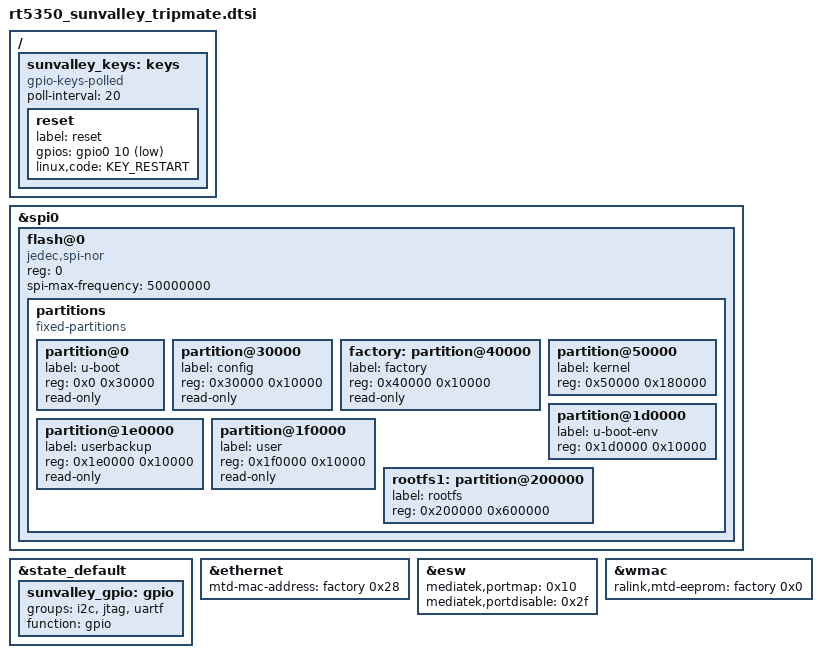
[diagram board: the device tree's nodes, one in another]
#include "rt5350.dtsi"

#include <dt-bindings/gpio/gpio.h>
#include <dt-bindings/input/input.h>

/ {
	sunvalley_keys: keys {
		compatible = "gpio-keys-polled";
		poll-interval = <20>;

		reset {
			label = "reset";
			gpios = <&gpio0 10 GPIO_ACTIVE_LOW>;
			linux,code = <KEY_RESTART>;
		};
	};
};

&spi0 {
	status = "okay";

	flash@0 {
		compatible = "jedec,spi-nor";
		reg = <0>;
		spi-max-frequency = <50000000>;

		partitions {
			compatible = "fixed-partitions";
			#address-cells = <1>;
			#size-cells = <1>;

			partition@0 {
				label = "u-boot";
				reg = <0x0 0x30000>;
				read-only;
			};

			partition@30000 {
				label = "config";
				reg = <0x30000 0x10000>;
				read-only;
			};

			factory: partition@40000 {
				label = "factory";
				reg = <0x40000 0x10000>;
				read-only;
			};

			partition@50000 {
				label = "kernel";
				reg = <0x50000 0x180000>;
			};

			partition@1d0000 {
				label = "u-boot-env";
				reg = <0x1d0000 0x10000>;
			};

			partition@1e0000 {
				label = "userbackup";
				reg = <0x1e0000 0x10000>;
				read-only;
			};

			partition@1f0000 {
				label = "user";
				reg = <0x1f0000 0x10000>;
				read-only;
			};

			rootfs1: partition@200000 {
				label = "rootfs";
				reg = <0x200000 0x600000>;
			};
		};
	};
};

&state_default {
	sunvalley_gpio: gpio {
		groups = "i2c", "jtag", "uartf";
		function = "gpio";
	};
};

&ethernet {
	mtd-mac-address = <&factory 0x28>;
};

&esw {
	mediatek,portmap = <0x10>;
	mediatek,portdisable = <0x2f>;
};

&wmac {
	ralink,mtd-eeprom = <&factory 0x0>;
};
